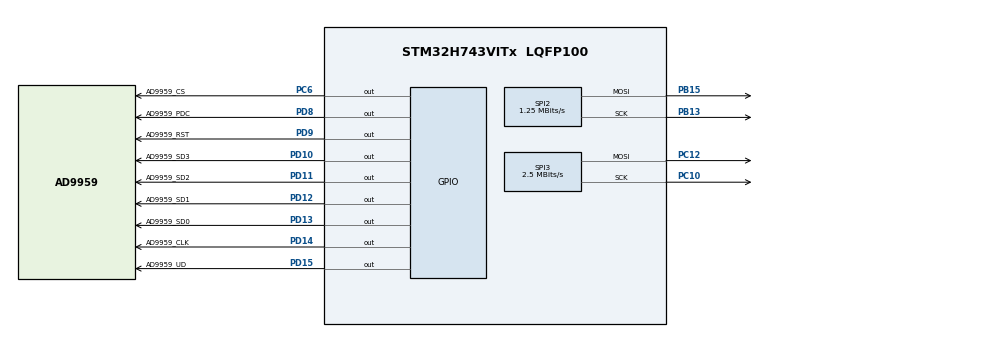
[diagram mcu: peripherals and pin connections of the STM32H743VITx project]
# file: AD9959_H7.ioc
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CORTEX_M7.default_mode_Activation=1
Mcu.Family=STM32H7
Mcu.Name=STM32H743VITx
Mcu.Package=LQFP100
NVIC.PriorityGroup=NVIC_PRIORITYGROUP_4
PA13\ (JTMS/SWDIO).Mode=Serial_Wire
PA13\ (JTMS/SWDIO).Signal=DEBUG_JTMS-SWDIO
PA14\ (JTCK/SWCLK).Mode=Serial_Wire
PA14\ (JTCK/SWCLK).Signal=DEBUG_JTCK-SWCLK
PB13.Mode=TX_Only_Simplex_Unidirect_Master
PB13.Signal=SPI2_SCK
PB15.Mode=TX_Only_Simplex_Unidirect_Master
PB15.Signal=SPI2_MOSI
PC10.Mode=TX_Only_Simplex_Unidirect_Master
PC10.Signal=SPI3_SCK
PC12.Mode=TX_Only_Simplex_Unidirect_Master
PC12.Signal=SPI3_MOSI
PC6.GPIO_Label=AD9959_CS
PC6.Signal=GPIO_Output
PD10.GPIO_Label=AD9959_SD3
PD10.Signal=GPIO_Output
PD11.GPIO_Label=AD9959_SD2
PD11.Signal=GPIO_Output
PD12.GPIO_Label=AD9959_SD1
PD12.Signal=GPIO_Output
PD13.GPIO_Label=AD9959_SD0
PD13.Signal=GPIO_Output
PD14.GPIO_Label=AD9959_CLK
PD14.Signal=GPIO_Output
PD15.GPIO_Label=AD9959_UD
PD15.Signal=GPIO_Output
PD8.GPIO_Label=AD9959_PDC
PD8.Signal=GPIO_Output
PD9.GPIO_Label=AD9959_RST
PD9.Signal=GPIO_Output
PH0-OSC_IN\ (PH0).Mode=HSE-External-Oscillator
PH0-OSC_IN\ (PH0).Signal=RCC_OSC_IN
PH1-OSC_OUT\ (PH1).Mode=HSE-External-Oscillator
PH1-OSC_OUT\ (PH1).Signal=RCC_OSC_OUT
ProjectManager.HeapSize=0x200
ProjectManager.StackSize=0x400
ProjectManager.TargetToolchain=STM32CubeIDE
RCC.ADCFreq_Value=129000000
RCC.APB1Freq_Value=80000000
RCC.APB2Freq_Value=80000000
RCC.APB3Freq_Value=80000000
RCC.APB4Freq_Value=80000000
RCC.CortexFreq_Value=80000000
RCC.DIVM1=4
RCC.DIVN1=10
RCC.HCLKFreq_Value=80000000
RCC.PLL2FRACN=0
RCC.PLL3FRACN=0
RCC.PLLFRACN=0
RCC.SYSCLKFreq_VALUE=80000000
RCC.SYSCLKSource=RCC_SYSCLKSOURCE_PLLCLK
RCC.USBFreq_Value=80000000
SPI2.BaudRatePrescaler=SPI_BAUDRATEPRESCALER_64
SPI2.CalculateBaudRate=1.25 MBits/s
SPI2.DataSize=SPI_DATASIZE_8BIT
SPI2.Direction=SPI_DIRECTION_2LINES_TXONLY
SPI2.Mode=SPI_MODE_MASTER
SPI2.VirtualType=VM_MASTER
SPI3.BaudRatePrescaler=SPI_BAUDRATEPRESCALER_32
SPI3.CalculateBaudRate=2.5 MBits/s
SPI3.DataSize=SPI_DATASIZE_8BIT
SPI3.Direction=SPI_DIRECTION_2LINES_TXONLY
SPI3.Mode=SPI_MODE_MASTER
SPI3.VirtualType=VM_MASTER
VP_MEMORYMAP_VS_MEMORYMAP.Mode=CurAppReg
board=custom

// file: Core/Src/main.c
/* USER CODE BEGIN Header */
/**
  ******************************************************************************
  * @file           : main.c
  * @brief          : Main program body
  ******************************************************************************
  * @attention
  *
  * Copyright (c) 2025 STMicroelectronics.
  * All rights reserved.
  *
  * This software is licensed under terms that can be found in the LICENSE file
  * in the root directory of this software component.
  * If no LICENSE file comes with this software, it is provided AS-IS.
  *
  ******************************************************************************
  */
/* USER CODE END Header */
#include "main.h"
#include "spi.h"
#include "gpio.h"

/* USER CODE BEGIN Includes */
#include "myad9959.h"

/* USER CODE END Includes */

void SystemClock_Config(void);
static void MPU_Config(void);

int main(void)
{

  /* MPU Configuration--------------------------------------------------------*/
  MPU_Config();

  /* MCU Configuration--------------------------------------------------------*/

  /* Reset of all peripherals, Initializes the Flash interface and the Systick. */
  HAL_Init();

  /* Configure the system clock */
  SystemClock_Config();

  /* Initialize all configured peripherals */
  MX_GPIO_Init();
  MX_SPI2_Init();
  MX_SPI3_Init();
  /* USER CODE BEGIN 2 */
  // 初始化AD9959芯片（GPIO初始化已由MX_GPIO_Init()完成）
  ad9959_init();

  ad9959_set_signal_out(1, 1000000, 0, 512);  // 设置通道0输出1MHz正弦波，幅度512
  ad9959_set_signal_out(2, 1000000, 90, 512);  // 设置通道1输出1MHz正弦波，幅度512
  ad9959_set_signal_out(3, 1000000, 180, 512);  // 设置通道2输出1MHz正弦波，幅度512
  /* USER CODE END 2 */

  /* Infinite loop */
  while (1)
  {

    /* USER CODE BEGIN 3 */
    ad9959_sweep_frequency(0,1000,2000000,1,1,0,512);  // 设置通道0线性扫频，频率从1kHz到2MHz，步进100Hz，相位0度，幅度512
    HAL_Delay(1000);
  }
  /* USER CODE END 3 */
}

void SystemClock_Config(void)
{
  RCC_OscInitTypeDef RCC_OscInitStruct = {0};
  RCC_ClkInitTypeDef RCC_ClkInitStruct = {0};

  /** Supply configuration update enable
  */
  HAL_PWREx_ConfigSupply(PWR_LDO_SUPPLY);

  /** Configure the main internal regulator output voltage
  */
  __HAL_PWR_VOLTAGESCALING_CONFIG(PWR_REGULATOR_VOLTAGE_SCALE3);

  while(!__HAL_PWR_GET_FLAG(PWR_FLAG_VOSRDY)) {}

  /** Initializes the RCC Oscillators according to the specified parameters
  * in the RCC_OscInitTypeDef structure.
  */
  RCC_OscInitStruct.OscillatorType = RCC_OSCILLATORTYPE_HSI;
  RCC_OscInitStruct.HSIState = RCC_HSI_DIV1;
  RCC_OscInitStruct.HSICalibrationValue = RCC_HSICALIBRATION_DEFAULT;
  RCC_OscInitStruct.PLL.PLLState = RCC_PLL_ON;
  RCC_OscInitStruct.PLL.PLLSource = RCC_PLLSOURCE_HSI;
  RCC_OscInitStruct.PLL.PLLM = 4;
  RCC_OscInitStruct.PLL.PLLN = 10;
  RCC_OscInitStruct.PLL.PLLP = 2;
  RCC_OscInitStruct.PLL.PLLQ = 2;
  RCC_OscInitStruct.PLL.PLLR = 2;
  RCC_OscInitStruct.PLL.PLLRGE = RCC_PLL1VCIRANGE_3;
  RCC_OscInitStruct.PLL.PLLVCOSEL = RCC_PLL1VCOMEDIUM;
  RCC_OscInitStruct.PLL.PLLFRACN = 0;
  if (HAL_RCC_OscConfig(&RCC_OscInitStruct) != HAL_OK)
  {
    Error_Handler();
  }

  /** Initializes the CPU, AHB and APB buses clocks
  */
  RCC_ClkInitStruct.ClockType = RCC_CLOCKTYPE_HCLK|RCC_CLOCKTYPE_SYSCLK
                              |RCC_CLOCKTYPE_PCLK1|RCC_CLOCKTYPE_PCLK2
                              |RCC_CLOCKTYPE_D3PCLK1|RCC_CLOCKTYPE_D1PCLK1;
  RCC_ClkInitStruct.SYSCLKSource = RCC_SYSCLKSOURCE_PLLCLK;
  RCC_ClkInitStruct.SYSCLKDivider = RCC_SYSCLK_DIV1;
  RCC_ClkInitStruct.AHBCLKDivider = RCC_HCLK_DIV1;
  RCC_ClkInitStruct.APB3CLKDivider = RCC_APB3_DIV1;
  RCC_ClkInitStruct.APB1CLKDivider = RCC_APB1_DIV1;
  RCC_ClkInitStruct.APB2CLKDivider = RCC_APB2_DIV1;
  RCC_ClkInitStruct.APB4CLKDivider = RCC_APB4_DIV1;

  if (HAL_RCC_ClockConfig(&RCC_ClkInitStruct, FLASH_LATENCY_1) != HAL_OK)
  {
    Error_Handler();
  }
}

 /* MPU Configuration */

void MPU_Config(void)
{
  MPU_Region_InitTypeDef MPU_InitStruct = {0};

  /* Disables the MPU */
  HAL_MPU_Disable();

  /** Initializes and configures the Region and the memory to be protected
  */
  MPU_InitStruct.Enable = MPU_REGION_ENABLE;
  MPU_InitStruct.Number = MPU_REGION_NUMBER0;
  MPU_InitStruct.BaseAddress = 0x0;
  MPU_InitStruct.Size = MPU_REGION_SIZE_4GB;
  MPU_InitStruct.SubRegionDisable = 0x87;
  MPU_InitStruct.TypeExtField = MPU_TEX_LEVEL0;
  MPU_InitStruct.AccessPermission = MPU_REGION_NO_ACCESS;
  MPU_InitStruct.DisableExec = MPU_INSTRUCTION_ACCESS_DISABLE;
  MPU_InitStruct.IsShareable = MPU_ACCESS_SHAREABLE;
  MPU_InitStruct.IsCacheable = MPU_ACCESS_NOT_CACHEABLE;
  MPU_InitStruct.IsBufferable = MPU_ACCESS_NOT_BUFFERABLE;

  HAL_MPU_ConfigRegion(&MPU_InitStruct);
  /* Enables the MPU */
  HAL_MPU_Enable(MPU_PRIVILEGED_DEFAULT);

}

void Error_Handler(void)
{
  __disable_irq();
  while (1)
  {
  }
}
